VERSION ""

NS_ :

BS_:

BU_: EECU VGT TCU SCU ABS/EBS/ESC Retarder EPS/HSCU IC DCDC BBM Display AEBS LKA ELC/ECAS HVAP VECU HCU BCM TPMS PAC ACM AVM CIOM LSCU EPB FNOx RNox ACU HCCB SCM ADCU UQS ROBD T-BOX Charge RKE DFD/DFMS LDWS FCWS BSD DCM VDR/BeiDou EMCU MCU(Axle) BMS CDC PEPS YRS Exhaust Ret. Engine Ret. AFS CCM CVG EAC SAS Tacho IVI ATC DST Camera Infotainment EHPS Gateway(INC) HOD BCA rADCU rEHPS

BO_ 2365547678 AutoDrive_ADCU: 8 ADCU
 SG_ CRC8 : 0|8@1+ (1.0,0.0) [0.0|255.0]  "" SCU,ABS/EBS/ESC,VECU,BCM,EHPS,BCA,rEHPS
 SG_ Counter : 8|4@1+ (1.0,0.0) [0.0|15.0]  "" SCU,ABS/EBS/ESC,VECU,BCM,EHPS,BCA,rEHPS
 SG_ AD Mode Enable PS : 16|2@1+ (1.0,0.0) [0.0|3.0]  "" SCU,ABS/EBS/ESC,VECU,BCM,EHPS,BCA,rEHPS
 SG_ AD Mode Engage PS : 20|2@1+ (1.0,0.0) [0.0|3.0]  "" SCU,ABS/EBS/ESC,VECU,BCM,EHPS,BCA,rEHPS

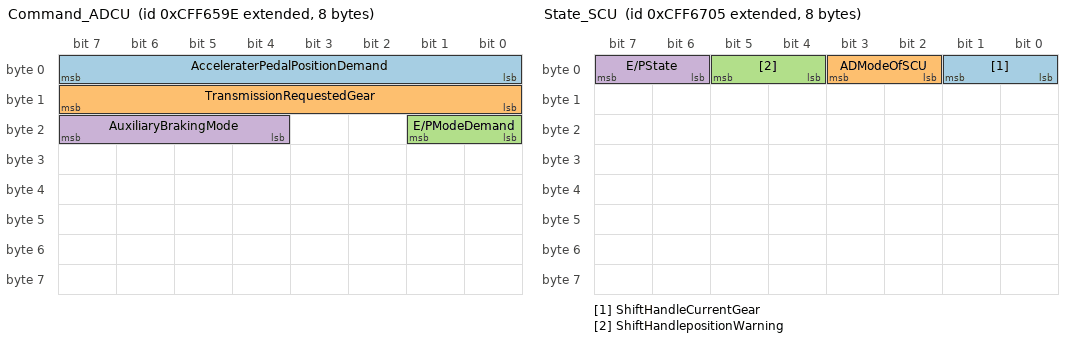
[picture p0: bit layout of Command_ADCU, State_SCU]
BO_ 2365547934 Command_ADCU: 8 ADCU
 SG_ AcceleraterPedalPositionDemand : 0|8@1+ (0.4,0.0) [0.0|100.0]  "" SCU,VECU
 SG_ TransmissionRequestedGear : 8|8@1+ (1.0,0.0) [0.0|255.0]  "" SCU,VECU
 SG_ E/PModeDemand : 16|2@1+ (1.0,0.0) [0.0|3.0]  "" SCU,VECU
 SG_ AuxiliaryBrakingMode : 20|4@1+ (1.0,0.0) [0.0|15.0]  "" SCU,VECU

BO_ 2365548293 State_SCU: 8 SCU
 SG_ ShiftHandleCurrentGear : 0|2@1+ (1.0,0.0) [0.0|3.0]  "" ADCU
 SG_ ADModeOfSCU : 2|2@1+ (1.0,0.0) [0.0|3.0]  "" ADCU
 SG_ ShiftHandlepositionWarning : 4|2@1+ (1.0,0.0) [0.0|3.0]  "" ADCU
 SG_ E/PState : 6|2@1+ (1.0,0.0) [0.0|3.0]  "" ADCU

BO_ 2565866755 ETC2_TCU: 8 TCU
 SG_ ETC2_TrmCurrGr : 24|8@1+ (1.0,-125.0) [0.0|130.0]  "gear value" ADCU
 SG_ ETC2_TrmSeldGr : 0|8@1+ (1.0,-125.0) [-125.0|125.0]  "gear value" ADCU

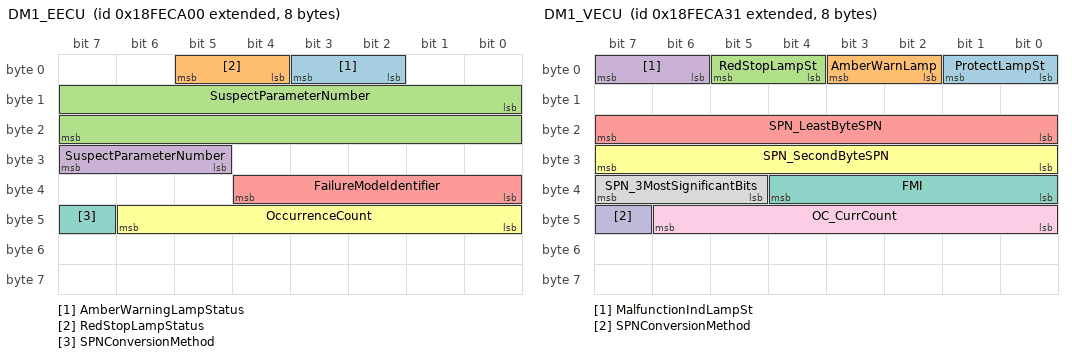
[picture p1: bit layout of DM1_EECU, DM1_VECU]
BO_ 2566834688 DM1_EECU: 8 EECU
 SG_ AmberWarningLampStatus : 2|2@1+ (1.0,0.0) [0.0|1.0]  "" ADCU
 SG_ RedStopLampStatus : 4|2@1+ (1.0,0.0) [0.0|1.0]  "" ADCU
 SG_ SuspectParameterNumber : 8|16@1+ (1.0,0.0) [0.0|65535.0]  "" ADCU
 SG_ SuspectParameterNumber : 29|3@1+ (1.0,0.0) [0.0|7.0]  "" ADCU
 SG_ FailureModeIdentifier : 32|5@1+ (1.0,0.0) [0.0|31.0]  "" ADCU
 SG_ OccurrenceCount : 40|7@1+ (1.0,0.0) [0.0|127.0]  "" ADCU
 SG_ SPNConversionMethod : 47|1@1+ (1.0,0.0) [0.0|1.0]  "" ADCU

BO_ 2566834691 DM1_TCU: 8 TCU
 SG_ DM1_TCU_ProttectLmpSt : 0|2@1+ (1.0,0.0) [0.0|3.0]  "" ADCU
 SG_ DM1_TCU_AmberWarnLmpSt : 2|2@1+ (1.0,0.0) [0.0|3.0]  "" ADCU
 SG_ DM1_TCU_RedStopLmpSt : 4|2@1+ (1.0,0.0) [0.0|3.0]  "" ADCU
 SG_ DM1_TCU_MalFuncIndLmpSt : 6|2@1+ (1.0,0.0) [0.0|3.0]  "" ADCU
 SG_ DM1_TCU_FlsProtectLmpSt : 8|2@1+ (1.0,0.0) [0.0|3.0]  "" ADCU
 SG_ DM1_TCU_FlsAmbWarnLmpSt : 10|2@1+ (1.0,0.0) [0.0|3.0]  "" ADCU
 SG_ DM1_TCU_FlsRedStopLmpSt : 12|2@1+ (1.0,0.0) [0.0|3.0]  "" ADCU
 SG_ DM1_TCU_FlsMalFuncIndLmpSt : 14|2@1+ (1.0,0.0) [0.0|3.0]  "" ADCU
 SG_ DM1_TCU_SPN_LSB : 16|19@1+ (1.0,0.0) [0.0|524287.0]  "" ADCU
 SG_ DM1_TCU_SPN_SecByte : 16|19@1+ (1.0,0.0) [0.0|524287.0]  "" ADCU
 SG_ DM1_TCU_SPN_MSB : 16|19@1+ (1.0,0.0) [0.0|524287.0]  "" ADCU
 SG_ DM1_TCU_FailureModeIndicato : 32|5@1+ (1.0,0.0) [0.0|31.0]  "" ADCU
 SG_ DM1_TCU_OccurentceCnt : 40|7@1+ (1.0,0.0) [0.0|127.0]  "" ADCU
 SG_ DM1_TCU_SPNConversionMethod : 47|1@1+ (1.0,0.0) [0.0|1.0]  "" ADCU

BO_ 2566834737 DM1_VECU: 8 VECU
 SG_ ProtectLampSt  : 0|2@1+ (1.0,0.0) [0.0|3.0]  "" ADCU
 SG_ AmberWarnLamp  : 2|2@1+ (1.0,0.0) [0.0|3.0]  "" ADCU
 SG_ RedStopLampSt  : 4|2@1+ (1.0,0.0) [0.0|3.0]  "" ADCU
 SG_ MalfunctionIndLampSt : 6|2@1+ (1.0,0.0) [0.0|3.0]  "" ADCU
 SG_ SPN_LeastByteSPN : 16|8@1+ (1.0,0.0) [0.0|255.0]  "" ADCU
 SG_ SPN_SecondByteSPN : 24|8@1+ (1.0,0.0) [0.0|255.0]  "" ADCU
 SG_ FMI : 32|5@1+ (1.0,0.0) [0.0|31.0]  "" ADCU
 SG_ SPN_3MostSignificantBits : 37|3@1+ (1.0,0.0) [0.0|7.0]  "" ADCU
 SG_ OC_CurrCount : 40|7@1+ (1.0,0.0) [0.0|127.0]  "" ADCU
 SG_ SPNConversionMethod : 47|1@1+ (1.0,0.0) [0.0|1.0]  "" ADCU

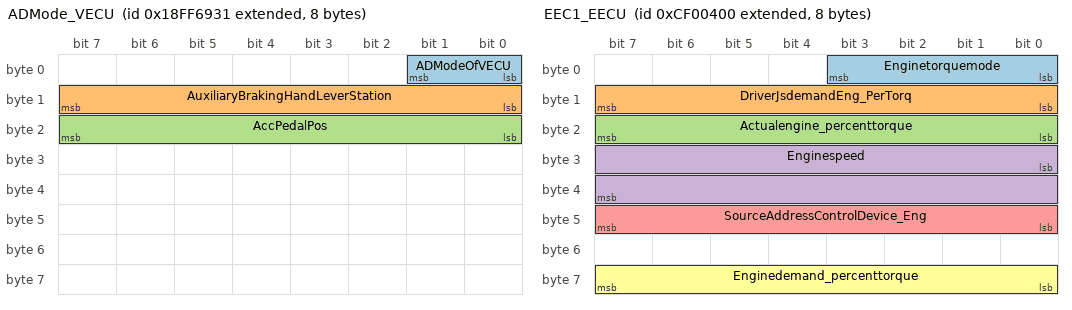
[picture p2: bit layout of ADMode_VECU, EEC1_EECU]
BO_ 2566875441 ADMode_VECU: 8 VECU
 SG_ ADModeOfVECU : 0|2@1+ (1.0,0.0) [0.0|3.0]  "" ADCU
 SG_ AuxiliaryBrakingHandLeverStation : 8|8@1+ (1.0,0.0) [0.0|255.0]  "" ADCU
 SG_ AccPedalPos : 16|8@1+ (0.4,0.0) [0.0|100.0]  "%" ADCU

BO_ 2364539904 EEC1_EECU: 8 EECU
 SG_ Enginetorquemode : 0|4@1+ (1.0,0.0) [0.0|15.0]  "" ABS/EBS/ESC,AEBS,ELC/ECAS,VECU,ADCU,EHPS
 SG_ DriverJsdemandEng_PerTorq : 8|8@1+ (1.0,-1.25) [-125.0|125.0]  "%" ABS/EBS/ESC,AEBS,ELC/ECAS,VECU,ADCU,EHPS
 SG_ Actualengine_percenttorque : 16|8@1+ (1.0,-1.25) [-125.0|125.0]  "%" ABS/EBS/ESC,AEBS,ELC/ECAS,VECU,ADCU,EHPS
 SG_ Enginespeed : 24|16@1+ (0.125,0.0) [0.0|8031.875]  "rpm" ABS/EBS/ESC,AEBS,ELC/ECAS,VECU,ADCU,EHPS
 SG_ SourceAddressControlDevice_Eng : 40|8@1+ (1.0,0.0) [0.0|255.0]  "" ABS/EBS/ESC,AEBS,ELC/ECAS,VECU,ADCU,EHPS
 SG_ Enginedemand_percenttorque : 56|8@1+ (1.0,-1.25) [-125.0|125.0]  "%" ABS/EBS/ESC,AEBS,ELC/ECAS,VECU,ADCU,EHPS

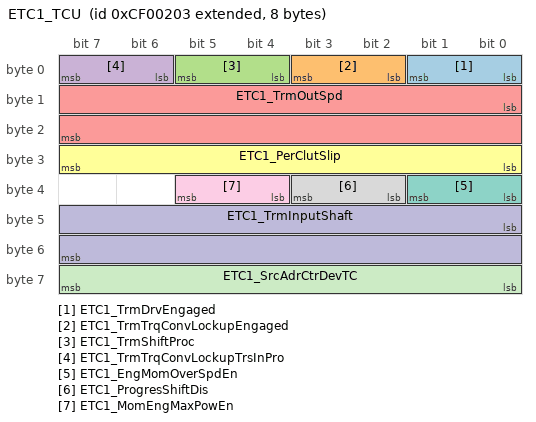
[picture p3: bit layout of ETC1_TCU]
BO_ 2364539395 ETC1_TCU: 8 TCU
 SG_ ETC1_TrmDrvEngaged : 0|2@1+ (1.0,0.0) [0.0|3.0]  "" ABS/EBS/ESC,VECU,ADCU
 SG_ ETC1_TrmTrqConvLockupEngaged : 2|2@1+ (1.0,0.0) [0.0|3.0]  "" ABS/EBS/ESC,VECU,ADCU
 SG_ ETC1_TrmShiftProc : 4|2@1+ (1.0,0.0) [0.0|3.0]  "" ABS/EBS/ESC,VECU,ADCU
 SG_ ETC1_TrmTrqConvLockupTrsInPro : 6|2@1+ (1.0,0.0) [0.0|3.0]  "" ABS/EBS/ESC,VECU,ADCU
 SG_ ETC1_TrmOutSpd : 8|16@1+ (0.125,0.0) [0.0|8191.875]  "rpm" ABS/EBS/ESC,VECU,ADCU
 SG_ ETC1_PerClutSlip : 24|8@1+ (0.4,0.0) [0.0|100.0]  "%" ABS/EBS/ESC,VECU,ADCU
 SG_ ETC1_EngMomOverSpdEn : 32|2@1+ (1.0,0.0) [0.0|3.0]  "" ABS/EBS/ESC,VECU,ADCU
 SG_ ETC1_ProgresShiftDis : 34|2@1+ (1.0,0.0) [0.0|3.0]  "" ABS/EBS/ESC,VECU,ADCU
 SG_ ETC1_MomEngMaxPowEn : 36|2@1+ (1.0,0.0) [0.0|3.0]  "" ABS/EBS/ESC,VECU,ADCU
 SG_ ETC1_TrmInputShaft : 40|16@1+ (0.125,0.0) [0.0|8031.875]  " rpm" ABS/EBS/ESC,VECU,ADCU
 SG_ ETC1_SrcAdrCtrDevTC : 56|8@1+ (1.0,0.0) [0.0|255.0]  "SA" ABS/EBS/ESC,VECU,ADCU

BO_ 2566842624 LFC_EECU: 8 EECU
 SG_ EngineTripFuel : 0|32@1+ (0.5,0.0) [0.0|2105540607.5]  "L"
 SG_ EngineTotalFuelUsed : 32|32@1+ (0.5,0.0) [0.0|2105540607.5]  "L"

BO_ 2566875186 State_BCM: 8 BCM
 SG_ PowerOnSwitchOfADCU : 14|2@1+ (1.0,0.0) [0.0|3.0]  "" ADCU
 SG_ ActiveSwitchOfADCU : 16|2@1+ (1.0,0.0) [0.0|3.0]  "" ADCU

BO_ 2566801923 ETC7_TCU: 8 TCU
 SG_ ETC7_TrmRedyforBrkRelease : 8|2@1+ (1.0,0.0) [0.0|3.0]  "" SCU

CM_ " ";
CM_ SG_ 2365547678 CRC8 "校验";
CM_ SG_ 2365547678 Counter "计数";
CM_ SG_ 2365547678 AD Mode Enable PS "允许进入自动驾驶模式(ADU_PS)";
CM_ SG_ 2365547678 AD Mode Engage PS "请求进入自动驾驶模式(ADU_PS)";
CM_ SG_ 2365548293 ADModeOfSCU "SCU自动驾驶状态反馈";
CM_ SG_ 2365548293 ShiftHandlepositionWarning "TCU外发实际档位与开关旋钮档位不一致提醒";
CM_ SG_ 2365548293 E/PState "E/P自复位开关状态反馈";
CM_ SG_ 2565866755 ETC2_TrmCurrGr "The gear currently engaged in the transmission or the last gear engaged while the transmission is in the process of shifting to the new or selected gear.  Transitions toward a destination gear will not be indicated.  Once the selected gear has been engaged then Transmission Current Gear (SPN 523) will reflect that gear.



Negative values are reverse gears, positive values are forward gears, zero is neutral, 251 (FBh) is park.";
CM_ SG_ 2565866755 ETC2_TrmSeldGr "The gear that the transmission will attempt to achieve during the current shift if a shift is in progress, or the next shift if one is pending (i.e., waiting for torque reduction to initiate the shift).



Negative values are reverse gears, positive values are forward gears, zero is neutral, 251 (FBh) is park.";
CM_ SG_ 2566834691 DM1_TCU_ProttectLmpSt "保护灯状态";
CM_ SG_ 2566834691 DM1_TCU_AmberWarnLmpSt "黄色信号灯状态";
CM_ SG_ 2566834691 DM1_TCU_RedStopLmpSt "红色停止灯状态";
CM_ SG_ 2566834691 DM1_TCU_MalFuncIndLmpSt "Malfunction Indicator Lamp";
CM_ SG_ 2566834691 DM1_TCU_FlsProtectLmpSt "Flash Protect Lamp";
CM_ SG_ 2566834691 DM1_TCU_FlsAmbWarnLmpSt "Flash Amber Warning Lamp (AWL)";
CM_ SG_ 2566834691 DM1_TCU_FlsRedStopLmpSt "Flash Red Stop Lamp (RSL)";
CM_ SG_ 2566834691 DM1_TCU_FlsMalFuncIndLmpSt "Flash Malfunction Indicator Lamp";
CM_ SG_ 2566834691 DM1_TCU_SPN_LSB "TCU的SPN";
CM_ SG_ 2566834691 DM1_TCU_FailureModeIndicato "失败模式指示";
CM_ SG_ 2566834691 DM1_TCU_OccurentceCnt "故障计数";
CM_ SG_ 2566834691 DM1_TCU_SPNConversionMethod "SPN转换方式";
CM_ SG_ 2566875441 ADModeOfVECU "VECU自动驾驶状态反馈";
CM_ SG_ 2566875441 AuxiliaryBrakingHandLeverStation "辅助制动拨杆位置反馈";
CM_ SG_ 2566875441 AccPedalPos "物理油门踏板位置";
CM_ SG_ 2364539904 Enginetorquemode "Engine Torque Mode";
CM_ SG_ 2364539904 DriverJsdemandEng_PerTorq "Engine Torque Percentage Based on Driver's Intention";
CM_ SG_ 2364539904 Actualengine_percenttorque "Actual Torque Percentage of Engine";
CM_ SG_ 2364539904 Enginespeed "engine speed";
CM_ SG_ 2364539904 SourceAddressControlDevice_Eng "Source address of engine control device";
CM_ SG_ 2364539904 Enginedemand_percenttorque "Percentage of engine required torque";
CM_ SG_ 2364539395 ETC1_TrmDrvEngaged "Driveline engaged indicates the transmission controlled portion of the driveline is engaged sufficiently to allow a transfer of torque through the transmission.  Driveline engaged is ACTIVE whenever the transmission is in gear and the clutch (if controlled by the transmission controller) is less than 100% clutch slip (clutch able to transfer torque).  This parameter should be used in conjunction with the parameter "Shift in Process" (SPN 574).  While a shift is in process, the receiver should not assume that the driveline is either fully engaged or disengaged (i.e., cruise control).
";
CM_ SG_ 2364539395 ETC1_TrmTrqConvLockupEngaged "State signal which indicates whether the torque converter lockup is engaged.
";
CM_ SG_ 2364539395 ETC1_TrmShiftProc "Indicates that the transmission is in process of shifting from the current gear to the selected gear. This state is generally ACTIVE during the entire time that the transmission controls the vehicle during a shift. This includes any transmission clutch control, all engine control sequences, pulling to transmission neutral, and engaging the destination gear (e.g., until it is no longer sending commands and/or limits to the engine). See also SPN 560. (See Figure SPN574_A)



This state is INACTIVE during other engine control such as torque limiting outside of a shift.
";
CM_ SG_ 2364539395 ETC1_TrmTrqConvLockupTrsInPro "State signal indicating whether or not the transmission torque converter lock up clutch is transitioning between being applied and being released.  The broadcast value should be set to 01b as soon as an apply or release of the lockup clutch is initiated, and then set to 00b once the given transition is complete.  This parameter is a companion to SPN 573 Transmission Torque Converter Lockup Engaged.
";
CM_ SG_ 2364539395 ETC1_TrmOutSpd "Calculated speed of the transmission 1 output shaft.";
CM_ SG_ 2364539395 ETC1_PerClutSlip "Parameter which represents the ratio of input shaft speed to current engine speed (in percent).



Percent Clutch Slip = ((Engine rpm - Input shaft rpm)/(Engine rpm)) x 100";
CM_ SG_ 2364539395 ETC1_EngMomOverSpdEn "Command signal used to indicate that the engine speed may be boosted up to the maximum engine overspeed value to accommodate transmission downshifts.  The maximum time for overspeed is limited by the time defined in the engine configuration message (see PGN 65,251).  The transmission module must command a "override disabled" state at least once before the engine will accept a subsequent request for overspeed.
";
CM_ SG_ 2364539395 ETC1_ProgresShiftDis "Command signal used to indicate that progressive shifting by the engine should be disallowed.
";
CM_ SG_ 2364539395 ETC1_MomEngMaxPowEn "Momentarily Requesting highest torque map from the engine control
";
CM_ SG_ 2364539395 ETC1_TrmInputShaft "Rotational velocity of the primary shaft transferring power into the first transmission.  When a torque converter is present, it is the output of the torque converter.



Note:



Single input shaft transmissions should use SPN 161 (Transmission Input Shaft Speed).

Multiple input shaft transmissions should use SPN 5960 and 5961 (DCT Input Shaft 1 and 2 Speeds).



For maximum compatibility, a multiple input shaft speed transmission may also broadcast SPN 161 as a

virtual or current inputshaft speed with the following logic:



Transmission Input Shaft Speed = DCT Input Shaft 1 Speed when shaft 1 is engaged.

Transmission Input Shaft Speed = DCT Input Shaft 2 Speed when shaft 2 is engaged.

Transmission Input Shaft Speed = Transitional interpolated value when shifting between shaft 1 and 2.";
CM_ SG_ 2364539395 ETC1_SrcAdrCtrDevTC "The source address of the SAE J1939 device currently controlling the transmission. Its value may be the source address of the ECU transmitting the message (which means that no external SAE J1939 message is providing the active command) or the source address of the SAE J1939 ECU that is currently providing the active command in a TSC1 (see PGN 0) or similar message.  Note that if this parameter value is the same as the source address of the device transmitting it, the control may be due to a message on a non-SAE J1939 data link such as SAE J1922 or a proprietary link.";
CM_ SG_ 2566842624 EngineTripFuel "Fuel consumption during engine operation";
CM_ SG_ 2566842624 EngineTotalFuelUsed "Total Engine Oil Consumption";
CM_ SG_ 2566875186 PowerOnSwitchOfADCU "AD系统开关";
CM_ SG_ 2566875186 ActiveSwitchOfADCU "自动驾驶激活开关";
CM_ SG_ 2566801923 ETC7_TrmRedyforBrkRelease "This parameter indicates that enough torque / motive force is available at the transmission output shaft to release all the brakes without a risk of unintentional movement in the opposite direction.

00b = Transmission Not Ready for Brake Release
01b = Transmission Ready for Brake Release
10b = Error
11b = Not available";

    BA_DEF_ BO_  "GenMsgSendType" ENUM  "cyclic","Event","IfActive","OnRequest","CA","CE","NoMsgSendType";
    BA_DEF_ BO_  "GenMsgCycleTime" INT 0 0;
    BA_DEF_ SG_  "GenSigSendType" ENUM  "cyclic","OnChange","OnWrite","IfActive","OnChangeWithRepetition","OnWriteWithRepetition","IfActiveWithRepetition","NoSigSendType","OnChangeAndIfActive","OnChangeAndIfActiveWithRepetition","CA", "CE","Event";
    BA_DEF_  "DBName" STRING ;
    BA_DEF_ SG_  "SPN" INT 0 0;
    BA_DEF_  "NMIdType" ENUM  "0: standard (11 bit, default)","1: extended (29 bit)";
    BA_DEF_  "NmMessageCount" INT 0 256;
    BA_DEF_ SG_  "GenSigEVName" STRING ;
    BA_DEF_ SG_  "GenSigILSupport" ENUM  "Yes","No";
    BA_DEF_ BO_  "GenMsgILSupport" ENUM  "Yes","No";
    BA_DEF_ BO_  "GenMsgRequestable" INT 0 1;
    BA_DEF_ BO_  "VFrameFormat" ENUM  "StandardCAN","ExtendedCAN","reserved","J1939PG";
    BA_DEF_ BU_  "NodeLayerModules" STRING ;
    BA_DEF_ BU_  "NmStationAddress" INT 0 255;
    BA_DEF_  "BusType" STRING ;

    BA_DEF_DEF_  "GenMsgSendType" "cyclic";
    BA_DEF_DEF_  "GenMsgCycleTime" 0;
    BA_DEF_DEF_  "GenSigSendType" "cyclic";

    BA_DEF_DEF_  "DBName" "";
    BA_DEF_DEF_  "SPN" 0;
    BA_DEF_DEF_  "NMIdType" "0: standard (11 bit, default)";
    BA_DEF_DEF_  "NmMessageCount" 128;
    BA_DEF_DEF_  "GenSigEVName" "Env@Nodename_@Signame";
    BA_DEF_DEF_  "GenSigILSupport" "Yes";
    BA_DEF_DEF_  "GenMsgILSupport" "Yes";
    BA_DEF_DEF_  "GenMsgRequestable" 1;
    BA_DEF_DEF_  "VFrameFormat" "J1939PG";
    BA_DEF_DEF_  "NodeLayerModules" "oseknm01.dll,CANoeILNLVector.dll,J1939_IL.dll";
    BA_DEF_DEF_  "NmStationAddress" 254;
    BA_DEF_DEF_  "BusType" "";
BA_ "DBName" "通讯矩阵- 赢彻B1-I-CAN0724";
    BA_ "BusType" "J1939";
BA_ "GenMsgCycleTime"BO_ 2365547678 100;
BA_ "GenMsgCycleTime"BO_ 2365547934 10;
BA_ "SPN" SG_ 2365547934 TransmissionRequestedGear 525;
BA_ "GenMsgCycleTime"BO_ 2365548293 50;
BA_ "GenMsgCycleTime"BO_ 2565866755 100;
BA_ "SPN" SG_ 2565866755 ETC2_TrmCurrGr 523;
BA_ "SPN" SG_ 2565866755 ETC2_TrmSeldGr 524;
BA_ "GenMsgCycleTime"BO_ 2566834688 1000;
BA_ "SPN" SG_ 2566834688 AmberWarningLampStatus 623;
BA_ "SPN" SG_ 2566834688 RedStopLampStatus 624;
BA_ "SPN" SG_ 2566834688 SuspectParameterNumber 1214;
BA_ "SPN" SG_ 2566834688 SuspectParameterNumber 1214;
BA_ "SPN" SG_ 2566834688 FailureModeIdentifier 1215;
BA_ "SPN" SG_ 2566834688 OccurrenceCount 1216;
BA_ "SPN" SG_ 2566834688 SPNConversionMethod 1706;
BA_ "GenMsgCycleTime"BO_ 2566834691 1000;
BA_ "SPN" SG_ 2566834691 DM1_TCU_ProttectLmpSt 987;
BA_ "SPN" SG_ 2566834691 DM1_TCU_AmberWarnLmpSt 624;
BA_ "SPN" SG_ 2566834691 DM1_TCU_RedStopLmpSt 623;
BA_ "SPN" SG_ 2566834691 DM1_TCU_MalFuncIndLmpSt 1213;
BA_ "SPN" SG_ 2566834691 DM1_TCU_FlsProtectLmpSt 3041;
BA_ "SPN" SG_ 2566834691 DM1_TCU_FlsAmbWarnLmpSt 3040;
BA_ "SPN" SG_ 2566834691 DM1_TCU_FlsRedStopLmpSt 3039;
BA_ "SPN" SG_ 2566834691 DM1_TCU_FlsMalFuncIndLmpSt 3038;
BA_ "SPN" SG_ 2566834691 DM1_TCU_SPN_LSB 1214;
BA_ "SPN" SG_ 2566834691 DM1_TCU_SPN_SecByte 1214;
BA_ "SPN" SG_ 2566834691 DM1_TCU_SPN_MSB 1214;
BA_ "SPN" SG_ 2566834691 DM1_TCU_FailureModeIndicato 1215;
BA_ "SPN" SG_ 2566834691 DM1_TCU_OccurentceCnt 1216;
BA_ "SPN" SG_ 2566834691 DM1_TCU_SPNConversionMethod 1706;
BA_ "GenMsgCycleTime"BO_ 2566834737 1000;
BA_ "SPN" SG_ 2566834737 ProtectLampSt  987;
BA_ "SPN" SG_ 2566834737 AmberWarnLamp  624;
BA_ "SPN" SG_ 2566834737 RedStopLampSt  623;
BA_ "SPN" SG_ 2566834737 MalfunctionIndLampSt 1213;
BA_ "SPN" SG_ 2566834737 SPN_LeastByteSPN 1214;
BA_ "SPN" SG_ 2566834737 SPN_SecondByteSPN 1214;
BA_ "SPN" SG_ 2566834737 FMI 1215;
BA_ "SPN" SG_ 2566834737 SPN_3MostSignificantBits 1214;
BA_ "SPN" SG_ 2566834737 OC_CurrCount 1216;
BA_ "SPN" SG_ 2566834737 SPNConversionMethod 1706;
BA_ "GenMsgCycleTime"BO_ 2566875441 100;
BA_ "SPN" SG_ 2566875441 AccPedalPos 91;
BA_ "GenMsgCycleTime"BO_ 2364539904 20;
BA_ "SPN" SG_ 2364539904 Enginetorquemode 899;
BA_ "SPN" SG_ 2364539904 DriverJsdemandEng_PerTorq 512;
BA_ "SPN" SG_ 2364539904 Actualengine_percenttorque 513;
BA_ "SPN" SG_ 2364539904 Enginespeed 190;
BA_ "SPN" SG_ 2364539904 SourceAddressControlDevice_Eng 1483;
BA_ "SPN" SG_ 2364539904 Enginedemand_percenttorque 2432;
BA_ "GenMsgCycleTime"BO_ 2364539395 10;
BA_ "SPN" SG_ 2364539395 ETC1_TrmDrvEngaged 560;
BA_ "SPN" SG_ 2364539395 ETC1_TrmTrqConvLockupEngaged 573;
BA_ "SPN" SG_ 2364539395 ETC1_TrmShiftProc 574;
BA_ "SPN" SG_ 2364539395 ETC1_TrmTrqConvLockupTrsInPro 4816;
BA_ "SPN" SG_ 2364539395 ETC1_TrmOutSpd 191;
BA_ "SPN" SG_ 2364539395 ETC1_PerClutSlip 522;
BA_ "SPN" SG_ 2364539395 ETC1_EngMomOverSpdEn 606;
BA_ "SPN" SG_ 2364539395 ETC1_ProgresShiftDis 607;
BA_ "SPN" SG_ 2364539395 ETC1_MomEngMaxPowEn 5015;
BA_ "SPN" SG_ 2364539395 ETC1_TrmInputShaft 161;
BA_ "SPN" SG_ 2364539395 ETC1_SrcAdrCtrDevTC 1482;
BA_ "GenMsgCycleTime"BO_ 2566842624 20;
BA_ "SPN" SG_ 2566842624 EngineTripFuel 182;
BA_ "SPN" SG_ 2566842624 EngineTotalFuelUsed 250;
BA_ "GenMsgCycleTime"BO_ 2566875186 100;
BA_ "GenMsgCycleTime"BO_ 2566801923 100;
BA_ "SPN" SG_ 2566801923 ETC7_TrmRedyforBrkRelease 3086;

VAL_ 2365547678 AD Mode Enable PS 0 "inhabit" 1 "enable" 2 "fail" 3 "reserve" ;
VAL_ 2365547678 AD Mode Engage PS 0 "inhabit" 1 "engage" 2 "reserve" 3 "reserve" ;
VAL_ 2365547934 TransmissionRequestedGear 224 "NoCommand" 254 "Error" 252 "ForwardDrivePosition" 223 "ReverseSelectorPosition" 222 "NeutralPosition" ;
VAL_ 2365547934 E/PModeDemand 0 "E" 1 "P" 2 "Reserved" 3 "Takenoaction" ;
VAL_ 2365548293 ShiftHandleCurrentGear 0 "N" 1 "D" 2 "R" 3 "Reserved" ;
VAL_ 2365548293 ADModeOfSCU 0 "Notready" 1 "Ready" 2 "Engaged" 3 "Fault" ;
VAL_ 2365548293 ShiftHandlepositionWarning 0 "nowarning" 1 "warning" ;
VAL_ 2365548293 E/PState 0 "Nopress" 1 "Pressed" 2 "Error" 3 "Reserved" ;
VAL_ 2566834688 AmberWarningLampStatus 0 "Off" 1 "On" ;
VAL_ 2566834688 RedStopLampStatus 0 "Off" 1 "On" ;
VAL_ 2566834691 DM1_TCU_ProttectLmpSt 0 "LampOff" 1 "LampOn" ;
VAL_ 2566834691 DM1_TCU_RedStopLmpSt 0 "LampOff" 1 "LampOn" ;
VAL_ 2566834737 ProtectLampSt  0 "LampOff" 1 "LampOn" ;
VAL_ 2566834737 AmberWarnLamp  0 "LampOff" 1 "LampOn" ;
VAL_ 2566834737 RedStopLampSt  0 "LampOff" 1 "LampOn" ;
VAL_ 2566834737 MalfunctionIndLampSt 0 "LampOff" 1 "LampOn" ;
VAL_ 2566875441 ADModeOfVECU 0 "Notready" 1 "Ready" 2 "Engaged" 3 "Fault" ;
VAL_ 2566875441 AuxiliaryBrakingHandLeverStation 0 "OFF" 1 "恒速档" 3 "1档减速-20%（缓速器）" 15 "2档减速-60%（缓速器）" 63 "3档减速-100%（缓速器+发动机制动）" ;
VAL_ 2364539904 Enginetorquemode 0 "Lowidlegovernor/norequest(defaultmode)" 1 "Acceleratorpedal/operatorselection" 2 "Cruisecontrol" 3 "PTOgovernor" 4 "Roadspeedgovernor" 5 "ASRcontrol" 6 "Transmissioncontrol" 7 "ABScontrol" 8 "Torquelimiting" 9 "Highspeedgovernor" 10 "Brakingsystem" 11 "Remoteaccelerator" 12 "Serviceprocedure" 13 "notdefined" 14 "Other" 15 "Notavailable" ;
VAL_ 2364539395 ETC1_TrmDrvEngaged 0 "Drivelinedisengaged" 1 "Drivelineengaged" 2 "Error" 3 "Notavailable" ;
VAL_ 2364539395 ETC1_TrmTrqConvLockupEngaged 0 "Torqueconverterlockupdisengaged" 1 "Torqueconverterlockupengaged" 2 "Error" 3 "Notavailable" ;
VAL_ 2364539395 ETC1_TrmShiftProc 0 "Shiftisnotinprocess" 1 "Shiftinprocess" 2 "Error" 3 "Notavailable" ;
VAL_ 2364539395 ETC1_TrmTrqConvLockupTrsInPro 0 "Transitionisnotinprocess" 1 "Transitionisinprocess" 2 "Error" 3 "Notavailable" ;
VAL_ 2364539395 ETC1_EngMomOverSpdEn 0 "Momentaryengineoverspeedisdisabled" 1 "Momentaryengineoverspeedisenabled" 2 "Reserved" 3 "Takenoaction" ;
VAL_ 2364539395 ETC1_ProgresShiftDis 0 "Progressiveshiftisnotdisabled" 1 "Progressiveshiftisdisabled" 2 "Reserved" 3 "Takenoaction" ;
VAL_ 2364539395 ETC1_MomEngMaxPowEn 0 "notrequestingmaximumpoweravailable" 1 "momentarilyrequestingmaximumpoweravailable" 2 "fault" 3 "notavailable" ;
VAL_ 2566875186 PowerOnSwitchOfADCU 0 "nopress" 1 "pressed" 3 "stick" ;
VAL_ 2566875186 ActiveSwitchOfADCU 0 "nopress" 1 "pressed" 3 "stick" ;
VAL_ 2566801923 ETC7_TrmRedyforBrkRelease 0 "TransmissionNotReadyforBrakeRelease" 1 "TransmissionReadyforBrakeRelease" 2 "Error" 3 "Notavailable" ;
